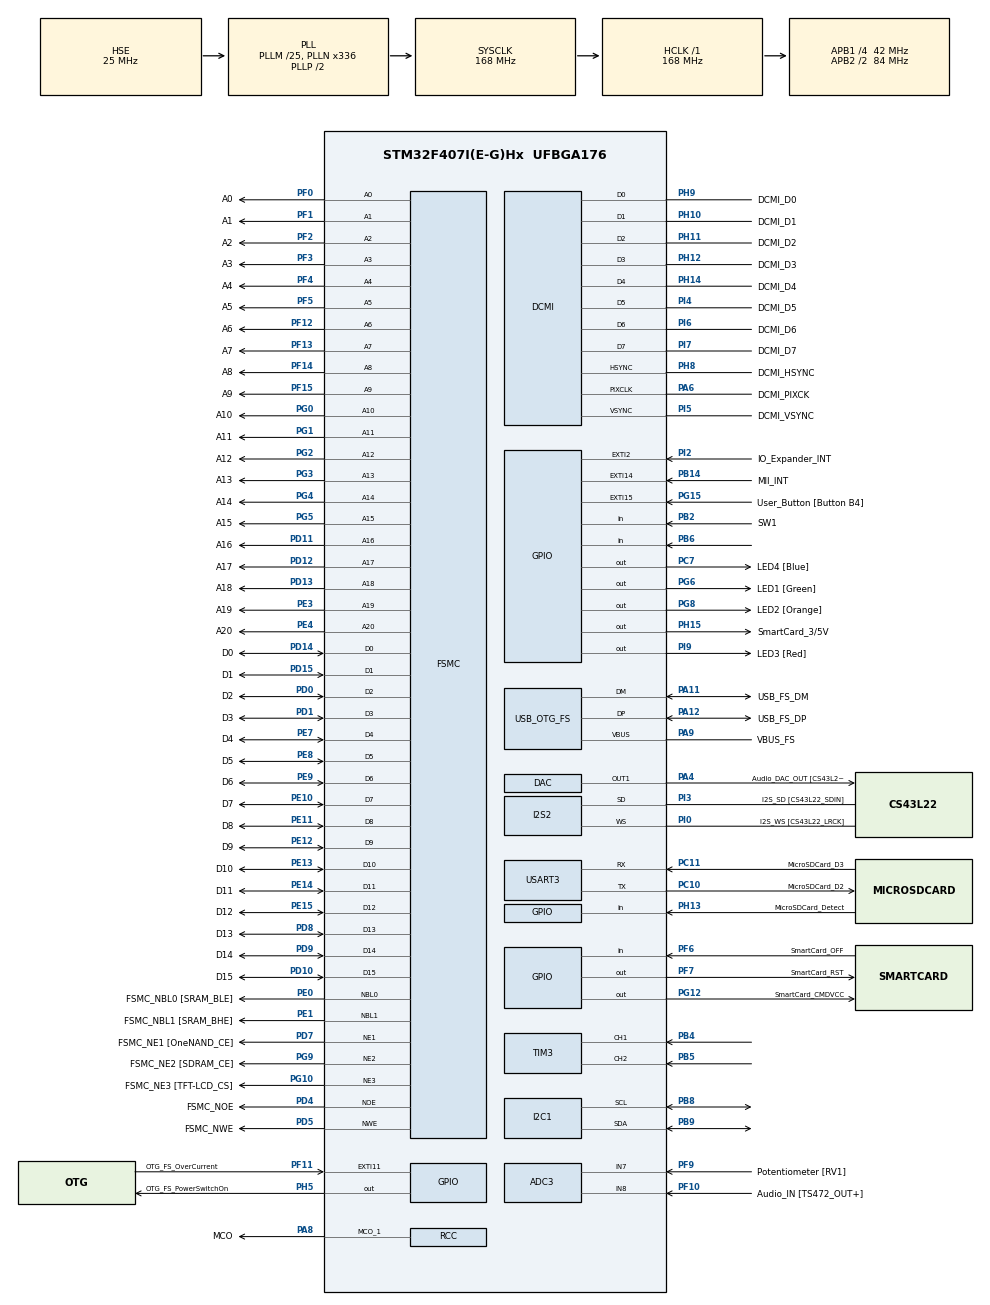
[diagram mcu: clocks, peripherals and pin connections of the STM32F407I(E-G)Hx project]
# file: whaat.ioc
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ADC3.Channel=ADC_CHANNEL_7
ADC3.Channel-0\#ChannelRegularConversion=ADC_CHANNEL_7
ADC3.NbrOfConversionFlag=1
ADC3.Rank-0\#ChannelRegularConversion=1
ADC3.SamplingTime-0\#ChannelRegularConversion=ADC_SAMPLETIME_3CYCLES
Mcu.Family=STM32F4
Mcu.Name=STM32F407I(E-G)Hx
Mcu.Package=UFBGA176
NVIC.OTG_FS_IRQn=true\:0\:0\:false\:false\:true\:true\:true\:true
NVIC.PriorityGroup=NVIC_PRIORITYGROUP_0
PA0-WKUP.GPIO_Label=WAKEUP [Button B2]
PA0-WKUP.Signal=SYS_WKUP
PA1.GPIO_Label=MII_RX_CLK/RMII_REF_CLK
PA1.GPIO_Mode=GPIO_MODE_AF_PP
PA1.GPIO_PuPd=GPIO_NOPULL
PA1.GPIO_Speed=GPIO_SPEED_FREQ_LOW
PA1.Signal=ETH_RX_CLK
PA10.GPIO_Label=USB_FS_ID
PA10.GPIO_Mode=GPIO_MODE_AF_PP
PA10.GPIO_PuPd=GPIO_NOPULL
PA10.GPIO_Speed=GPIO_SPEED_FREQ_LOW
PA10.Signal=USB_OTG_FS_ID
PA11.GPIO_Label=USB_FS_DM
PA11.GPIO_Mode=GPIO_MODE_AF_PP
PA11.GPIO_PuPd=GPIO_NOPULL
PA11.GPIO_Speed=GPIO_SPEED_FREQ_LOW
PA11.Mode=Device_Only
PA11.Signal=USB_OTG_FS_DM
PA12.GPIO_Label=USB_FS_DP
PA12.GPIO_Mode=GPIO_MODE_AF_PP
PA12.GPIO_PuPd=GPIO_NOPULL
PA12.GPIO_Speed=GPIO_SPEED_FREQ_LOW
PA12.Mode=Device_Only
PA12.Signal=USB_OTG_FS_DP
PA13.GPIO_Label=TMS/SWDIO
PA13.Mode=Serial_Wire
PA13.Signal=SYS_JTMS-SWDIO
PA14.GPIO_Label=TCK/SWCLK
PA14.Mode=Serial_Wire
PA14.Signal=SYS_JTCK-SWCLK
PA15.GPIO_Label=TDI
PA15.Signal=SYS_JTDI
PA2.GPIO_Label=MII_MDIO
PA2.GPIO_Mode=GPIO_MODE_AF_PP
PA2.GPIO_PuPd=GPIO_NOPULL
PA2.GPIO_Speed=GPIO_SPEED_FREQ_LOW
PA2.Signal=ETH_MDIO
PA3.GPIO_Label=ULPI_D0
PA3.GPIO_Mode=GPIO_MODE_AF_PP
PA3.GPIO_PuPd=GPIO_NOPULL
PA3.GPIO_Speed=GPIO_SPEED_FREQ_VERY_HIGH
PA3.Signal=USB_OTG_HS_ULPI_D0
PA4.GPIO_Label=Audio_DAC_OUT [CS43L22_AIN1]
PA4.GPIO_Mode=GPIO_MODE_ANALOG
PA4.GPIO_PuPd=GPIO_NOPULL
PA4.Signal=COMP_DAC1_group
PA5.GPIO_Label=ULPI_CLK
PA5.GPIO_Mode=GPIO_MODE_AF_PP
PA5.GPIO_PuPd=GPIO_NOPULL
PA5.GPIO_Speed=GPIO_SPEED_FREQ_VERY_HIGH
PA5.Signal=USB_OTG_HS_ULPI_CK
PA6.GPIO_Label=DCMI_PIXCK
PA6.GPIO_Mode=GPIO_MODE_AF_PP
PA6.GPIO_PuPd=GPIO_NOPULL
PA6.GPIO_Speed=GPIO_SPEED_FREQ_LOW
PA6.Mode=Slave_8_bits_External_Synchro
PA6.Signal=DCMI_PIXCLK
PA7.GPIO_Label=MII_RX_DV/RMII_CRSDV
PA7.GPIO_Mode=GPIO_MODE_AF_PP
PA7.GPIO_PuPd=GPIO_NOPULL
PA7.GPIO_Speed=GPIO_SPEED_FREQ_LOW
PA7.Signal=ETH_RX_DV
PA8.GPIO_Label=MCO
PA8.GPIO_Mode=GPIO_MODE_AF_PP
PA8.GPIO_PuPd=GPIO_NOPULL
PA8.GPIO_Speed=GPIO_SPEED_FREQ_LOW
PA8.Mode=Clock-out-1
PA8.Signal=RCC_MCO_1
PA9.GPIO_Label=VBUS_FS
PA9.GPIO_Mode=GPIO_MODE_INPUT
PA9.GPIO_PuPd=GPIO_NOPULL
PA9.Mode=Activate_VBUS
PA9.Signal=USB_OTG_FS_VBUS
PB0.GPIO_Label=ULPI_D1
PB0.GPIO_Mode=GPIO_MODE_AF_PP
PB0.GPIO_PuPd=GPIO_NOPULL
PB0.GPIO_Speed=GPIO_SPEED_FREQ_VERY_HIGH
PB0.Signal=USB_OTG_HS_ULPI_D1
PB1.GPIO_Label=ULPI_D2
PB1.GPIO_Mode=GPIO_MODE_AF_PP
PB1.GPIO_PuPd=GPIO_NOPULL
PB1.GPIO_Speed=GPIO_SPEED_FREQ_VERY_HIGH
PB1.Signal=USB_OTG_HS_ULPI_D2
PB10.GPIO_Label=ULPI_D3
PB10.GPIO_Mode=GPIO_MODE_AF_PP
PB10.GPIO_PuPd=GPIO_NOPULL
PB10.GPIO_Speed=GPIO_SPEED_FREQ_VERY_HIGH
PB10.Signal=USB_OTG_HS_ULPI_D3
PB11.GPIO_Label=ULPI_D4
PB11.GPIO_Mode=GPIO_MODE_AF_PP
PB11.GPIO_PuPd=GPIO_NOPULL
PB11.GPIO_Speed=GPIO_SPEED_FREQ_VERY_HIGH
PB11.Signal=USB_OTG_HS_ULPI_D4
PB12.GPIO_Label=ULPI_D5
PB12.GPIO_Mode=GPIO_MODE_AF_PP
PB12.GPIO_PuPd=GPIO_NOPULL
PB12.GPIO_Speed=GPIO_SPEED_FREQ_VERY_HIGH
PB12.Signal=USB_OTG_HS_ULPI_D5
PB13.GPIO_Label=ULPI_D6
PB13.GPIO_Mode=GPIO_MODE_AF_PP
PB13.GPIO_PuPd=GPIO_NOPULL
PB13.GPIO_Speed=GPIO_SPEED_FREQ_VERY_HIGH
PB13.Signal=USB_OTG_HS_ULPI_D6
PB14.GPIO_Label=MII_INT
PB14.GPIO_ModeDefaultEXTI=GPIO_MODE_EVT_RISING
PB14.GPIO_PuPd=GPIO_NOPULL
PB14.Signal=GPXTI14
PB2.GPIO_Label=SW1
PB2.GPIO_Mode=GPIO_MODE_INPUT
PB2.GPIO_PuPd=GPIO_NOPULL
PB2.Signal=GPIO_Input
PB3.GPIO_Label=TDO/SWO
PB3.Signal=SYS_JTDO-SWO
PB4.Signal=S_TIM3_CH1
PB5.Signal=S_TIM3_CH2
PB6.GPIO_PuPd=GPIO_PULLDOWN
PB6.Signal=GPIO_Input
PB7.GPIO_Label=FSMC_NL [OneNAND_AVD]
PB7.GPIO_Mode=GPIO_MODE_AF_PP
PB7.GPIO_PuPd=GPIO_NOPULL
PB7.GPIO_Speed=GPIO_SPEED_FREQ_LOW
PB7.Signal=FSMC_NL
PB8.Mode=I2C
PB8.Signal=I2C1_SCL
PB9.Mode=I2C
PB9.Signal=I2C1_SDA
PC0.GPIO_Label=ULPI_STP
PC0.GPIO_Mode=GPIO_MODE_AF_PP
PC0.GPIO_PuPd=GPIO_NOPULL
PC0.GPIO_Speed=GPIO_SPEED_FREQ_VERY_HIGH
PC0.Signal=USB_OTG_HS_ULPI_STP
PC1.GPIO_Label=MII_MDC
PC1.GPIO_Mode=GPIO_MODE_AF_PP
PC1.GPIO_PuPd=GPIO_NOPULL
PC1.GPIO_Speed=GPIO_SPEED_FREQ_LOW
PC1.Signal=ETH_MDC
PC10.GPIO_Label=MicroSDCard_D2
PC10.GPIO_Mode=GPIO_MODE_AF_PP
PC10.GPIO_PuPd=GPIO_NOPULL
PC10.GPIO_Speed=GPIO_SPEED_FREQ_LOW
PC10.Mode=Asynchronous
PC10.Signal=USART3_TX
PC11.GPIO_Label=MicroSDCard_D3
PC11.GPIO_Mode=GPIO_MODE_AF_PP
PC11.GPIO_PuPd=GPIO_NOPULL
PC11.GPIO_Speed=GPIO_SPEED_FREQ_LOW
PC11.Mode=Asynchronous
PC11.Signal=USART3_RX
PC12.GPIO_Label=MicroSDCard_CLK
PC12.GPIO_Mode=GPIO_MODE_AF_PP
PC12.GPIO_PuPd=GPIO_NOPULL
PC12.GPIO_Speed=GPIO_SPEED_FREQ_LOW
PC12.Signal=SDIO_CK
PC13-ANTI_TAMP.GPIO_Label=Anti_Tamper [Button B3]
PC13-ANTI_TAMP.Signal=RTC_AF1
PC14-OSC32_IN.GPIO_Label=PC14-OSC32_IN
PC14-OSC32_IN.Mode=LSE-External-Oscillator
PC14-OSC32_IN.Signal=RCC_OSC32_IN
PC15-OSC32_OUT.GPIO_Label=PC15-OSC32_OUT
PC15-OSC32_OUT.Mode=LSE-External-Oscillator
PC15-OSC32_OUT.Signal=RCC_OSC32_OUT
PC2.GPIO_Label=MII_TXD2
PC2.GPIO_Mode=GPIO_MODE_AF_PP
PC2.GPIO_PuPd=GPIO_NOPULL
PC2.GPIO_Speed=GPIO_SPEED_FREQ_LOW
PC2.Signal=ETH_TXD2
PC3.GPIO_Label=MII_TX_CLK
PC3.GPIO_Mode=GPIO_MODE_AF_PP
PC3.GPIO_PuPd=GPIO_NOPULL
PC3.GPIO_Speed=GPIO_SPEED_FREQ_LOW
PC3.Signal=ETH_TX_CLK
PC4.GPIO_Label=MII_RXD0
PC4.GPIO_Mode=GPIO_MODE_AF_PP
PC4.GPIO_PuPd=GPIO_NOPULL
PC4.GPIO_Speed=GPIO_SPEED_FREQ_LOW
PC4.Signal=ETH_RXD0
PC5.GPIO_Label=MII_RXD1
PC5.GPIO_Mode=GPIO_MODE_AF_PP
PC5.GPIO_PuPd=GPIO_NOPULL
PC5.GPIO_Speed=GPIO_SPEED_FREQ_LOW
PC5.Signal=ETH_RXD1
PC7.GPIO_Label=LED4 [Blue]
PC7.GPIO_Mode=GPIO_MODE_OUTPUT_PP
PC7.GPIO_ModeDefaultOutputPP=GPIO_MODE_OUTPUT_PP
PC7.GPIO_PuPd=GPIO_NOPULL
PC7.GPIO_Speed=GPIO_SPEED_FREQ_LOW
PC7.Signal=GPIO_Output
PC8.GPIO_Label=MicroSDCard_D0
PC8.GPIO_Mode=GPIO_MODE_AF_PP
PC8.GPIO_PuPd=GPIO_NOPULL
PC8.GPIO_Speed=GPIO_SPEED_FREQ_LOW
PC8.Signal=SDIO_D0
PC9.GPIO_Label=MicroSDCard_D1
PC9.GPIO_Mode=GPIO_MODE_AF_PP
PC9.GPIO_PuPd=GPIO_NOPULL
PC9.GPIO_Speed=GPIO_SPEED_FREQ_LOW
PC9.Signal=SDIO_D1
PD0.GPIO_Label=D2
PD0.GPIO_Mode=GPIO_MODE_AF_PP
PD0.GPIO_PuPd=GPIO_NOPULL
PD0.GPIO_Speed=GPIO_SPEED_FREQ_LOW
PD0.Signal=FSMC_D2_DA2
PD1.GPIO_Label=D3
PD1.GPIO_Mode=GPIO_MODE_AF_PP
PD1.GPIO_PuPd=GPIO_NOPULL
PD1.GPIO_Speed=GPIO_SPEED_FREQ_LOW
PD1.Signal=FSMC_D3_DA3
PD10.GPIO_Label=D15
PD10.GPIO_Mode=GPIO_MODE_AF_PP
PD10.GPIO_PuPd=GPIO_NOPULL
PD10.GPIO_Speed=GPIO_SPEED_FREQ_LOW
PD10.Signal=FSMC_D15_DA15
PD11.GPIO_Label=A16
PD11.GPIO_Mode=GPIO_MODE_AF_PP
PD11.GPIO_PuPd=GPIO_NOPULL
PD11.GPIO_Speed=GPIO_SPEED_FREQ_LOW
PD11.Signal=FSMC_A16_CLE
PD12.GPIO_Label=A17
PD12.GPIO_Mode=GPIO_MODE_AF_PP
PD12.GPIO_PuPd=GPIO_NOPULL
PD12.GPIO_Speed=GPIO_SPEED_FREQ_LOW
PD12.Signal=FSMC_A17_ALE
PD13.GPIO_Label=A18
PD13.GPIO_Mode=GPIO_MODE_AF_PP
PD13.GPIO_PuPd=GPIO_NOPULL
PD13.GPIO_Speed=GPIO_SPEED_FREQ_LOW
PD13.Signal=FSMC_A18
PD14.GPIO_Label=D0
PD14.GPIO_Mode=GPIO_MODE_AF_PP
PD14.GPIO_PuPd=GPIO_NOPULL
PD14.GPIO_Speed=GPIO_SPEED_FREQ_LOW
PD14.Signal=FSMC_D0_DA0
PD15.GPIO_Label=D1
PD15.GPIO_Mode=GPIO_MODE_AF_PP
PD15.GPIO_PuPd=GPIO_NOPULL
PD15.GPIO_Speed=GPIO_SPEED_FREQ_LOW
PD15.Signal=FSMC_D1_DA1
PD2.GPIO_Label=MicroSDCard_CMD
PD2.GPIO_Mode=GPIO_MODE_AF_PP
PD2.GPIO_PuPd=GPIO_NOPULL
PD2.GPIO_Speed=GPIO_SPEED_FREQ_LOW
PD2.Signal=SDIO_CMD
PD3.GPIO_Label=FSMC_CLK [OneNAND_CLK]
PD3.GPIO_Mode=GPIO_MODE_AF_PP
PD3.GPIO_PuPd=GPIO_NOPULL
PD3.GPIO_Speed=GPIO_SPEED_FREQ_LOW
PD3.Signal=FSMC_CLK
PD4.GPIO_Label=FSMC_NOE
PD4.GPIO_Mode=GPIO_MODE_AF_PP
PD4.GPIO_PuPd=GPIO_NOPULL
PD4.GPIO_Speed=GPIO_SPEED_FREQ_LOW
PD4.Signal=FSMC_NOE
PD5.GPIO_Label=FSMC_NWE
PD5.GPIO_Mode=GPIO_MODE_AF_PP
PD5.GPIO_PuPd=GPIO_NOPULL
PD5.GPIO_Speed=GPIO_SPEED_FREQ_LOW
PD5.Signal=FSMC_NWE
PD6.GPIO_Label=FSMC_NWAIT [OneNAND_RDY]
PD6.GPIO_Mode=GPIO_MODE_AF_PP
PD6.GPIO_PuPd=GPIO_NOPULL
PD6.GPIO_Speed=GPIO_SPEED_FREQ_LOW
PD6.Signal=FSMC_NWAIT
PD7.GPIO_Label=FSMC_NE1 [OneNAND_CE]
PD7.GPIO_Mode=GPIO_MODE_AF_PP
PD7.GPIO_PuPd=GPIO_NOPULL
PD7.GPIO_Speed=GPIO_SPEED_FREQ_LOW
PD7.Mode=NorPsramChipSelect1_1
PD7.Signal=FSMC_NE1
PD8.GPIO_Label=D13
PD8.GPIO_Mode=GPIO_MODE_AF_PP
PD8.GPIO_PuPd=GPIO_NOPULL
PD8.GPIO_Speed=GPIO_SPEED_FREQ_LOW
PD8.Signal=FSMC_D13_DA13
PD9.GPIO_Label=D14
PD9.GPIO_Mode=GPIO_MODE_AF_PP
PD9.GPIO_PuPd=GPIO_NOPULL
PD9.GPIO_Speed=GPIO_SPEED_FREQ_LOW
PD9.Signal=FSMC_D14_DA14
PE0.GPIO_Label=FSMC_NBL0 [SRAM_BLE]
PE0.GPIO_Mode=GPIO_MODE_AF_PP
PE0.GPIO_PuPd=GPIO_NOPULL
PE0.GPIO_Speed=GPIO_SPEED_FREQ_LOW
PE0.Signal=FSMC_NBL0
PE1.GPIO_Label=FSMC_NBL1 [SRAM_BHE]
PE1.GPIO_Mode=GPIO_MODE_AF_PP
PE1.GPIO_PuPd=GPIO_NOPULL
PE1.GPIO_Speed=GPIO_SPEED_FREQ_LOW
PE1.Signal=FSMC_NBL1
PE10.GPIO_Label=D7
PE10.GPIO_Mode=GPIO_MODE_AF_PP
PE10.GPIO_PuPd=GPIO_NOPULL
PE10.GPIO_Speed=GPIO_SPEED_FREQ_LOW
PE10.Signal=FSMC_D7_DA7
PE11.GPIO_Label=D8
PE11.GPIO_Mode=GPIO_MODE_AF_PP
PE11.GPIO_PuPd=GPIO_NOPULL
PE11.GPIO_Speed=GPIO_SPEED_FREQ_LOW
PE11.Signal=FSMC_D8_DA8
PE12.GPIO_Label=D9
PE12.GPIO_Mode=GPIO_MODE_AF_PP
PE12.GPIO_PuPd=GPIO_NOPULL
PE12.GPIO_Speed=GPIO_SPEED_FREQ_LOW
PE12.Signal=FSMC_D9_DA9
PE13.GPIO_Label=D10
PE13.GPIO_Mode=GPIO_MODE_AF_PP
PE13.GPIO_PuPd=GPIO_NOPULL
PE13.GPIO_Speed=GPIO_SPEED_FREQ_LOW
PE13.Signal=FSMC_D10_DA10
PE14.GPIO_Label=D11
PE14.GPIO_Mode=GPIO_MODE_AF_PP
PE14.GPIO_PuPd=GPIO_NOPULL
PE14.GPIO_Speed=GPIO_SPEED_FREQ_LOW
PE14.Signal=FSMC_D11_DA11
PE15.GPIO_Label=D12
PE15.GPIO_Mode=GPIO_MODE_AF_PP
PE15.GPIO_PuPd=GPIO_NOPULL
PE15.GPIO_Speed=GPIO_SPEED_FREQ_LOW
PE15.Signal=FSMC_D12_DA12
PE2.GPIO_Label=TRACE_CLK
PE2.Signal=SYS_TRACECLK
PE3.GPIO_Label=A19
PE3.GPIO_Mode=GPIO_MODE_AF_PP
PE3.GPIO_PuPd=GPIO_NOPULL
PE3.GPIO_Speed=GPIO_SPEED_FREQ_LOW
PE3.Signal=FSMC_A19
PE4.GPIO_Label=A20
PE4.GPIO_Mode=GPIO_MODE_AF_PP
PE4.GPIO_PuPd=GPIO_NOPULL
PE4.GPIO_Speed=GPIO_SPEED_FREQ_LOW
PE4.Signal=FSMC_A20
PE5.GPIO_Label=TRACE_D2
PE5.Signal=SYS_TRACED2
PE6.GPIO_Label=TRACE_D3
PE6.Signal=SYS_TRACED3
PE7.GPIO_Label=D4
PE7.GPIO_Mode=GPIO_MODE_AF_PP
PE7.GPIO_PuPd=GPIO_NOPULL
PE7.GPIO_Speed=GPIO_SPEED_FREQ_LOW
PE7.Signal=FSMC_D4_DA4
PE8.GPIO_Label=D5
PE8.GPIO_Mode=GPIO_MODE_AF_PP
PE8.GPIO_PuPd=GPIO_NOPULL
PE8.GPIO_Speed=GPIO_SPEED_FREQ_LOW
PE8.Signal=FSMC_D5_DA5
PE9.GPIO_Label=D6
PE9.GPIO_Mode=GPIO_MODE_AF_PP
PE9.GPIO_PuPd=GPIO_NOPULL
PE9.GPIO_Speed=GPIO_SPEED_FREQ_LOW
PE9.Signal=FSMC_D6_DA6
PF0.GPIO_Label=A0
PF0.GPIO_Mode=GPIO_MODE_AF_PP
PF0.GPIO_PuPd=GPIO_NOPULL
PF0.GPIO_Speed=GPIO_SPEED_FREQ_LOW
PF0.Signal=FSMC_A0
PF1.GPIO_Label=A1
PF1.GPIO_Mode=GPIO_MODE_AF_PP
PF1.GPIO_PuPd=GPIO_NOPULL
PF1.GPIO_Speed=GPIO_SPEED_FREQ_LOW
PF1.Signal=FSMC_A1
PF10.GPIO_Label=Audio_IN [TS472_OUT+]
PF10.GPIO_Mode=GPIO_MODE_ANALOG
PF10.GPIO_PuPd=GPIO_NOPULL
PF10.Mode=IN8
PF10.Signal=ADC3_IN8
PF11.GPIO_Label=OTG_FS_OverCurrent
PF11.GPIO_ModeDefaultEXTI=GPIO_MODE_EVT_RISING
PF11.GPIO_PuPd=GPIO_NOPULL
PF11.Signal=GPXTI11
PF12.GPIO_Label=A6
PF12.GPIO_Mode=GPIO_MODE_AF_PP
PF12.GPIO_PuPd=GPIO_NOPULL
PF12.GPIO_Speed=GPIO_SPEED_FREQ_LOW
PF12.Signal=FSMC_A6
PF13.GPIO_Label=A7
PF13.GPIO_Mode=GPIO_MODE_AF_PP
PF13.GPIO_PuPd=GPIO_NOPULL
PF13.GPIO_Speed=GPIO_SPEED_FREQ_LOW
PF13.Signal=FSMC_A7
PF14.GPIO_Label=A8
PF14.GPIO_Mode=GPIO_MODE_AF_PP
PF14.GPIO_PuPd=GPIO_NOPULL
PF14.GPIO_Speed=GPIO_SPEED_FREQ_LOW
PF14.Signal=FSMC_A8
PF15.GPIO_Label=A9
PF15.GPIO_Mode=GPIO_MODE_AF_PP
PF15.GPIO_PuPd=GPIO_NOPULL
PF15.GPIO_Speed=GPIO_SPEED_FREQ_LOW
PF15.Signal=FSMC_A9
PF2.GPIO_Label=A2
PF2.GPIO_Mode=GPIO_MODE_AF_PP
PF2.GPIO_PuPd=GPIO_NOPULL
PF2.GPIO_Speed=GPIO_SPEED_FREQ_LOW
PF2.Signal=FSMC_A2
PF3.GPIO_Label=A3
PF3.GPIO_Mode=GPIO_MODE_AF_PP
PF3.GPIO_PuPd=GPIO_NOPULL
PF3.GPIO_Speed=GPIO_SPEED_FREQ_LOW
PF3.Signal=FSMC_A3
PF4.GPIO_Label=A4
PF4.GPIO_Mode=GPIO_MODE_AF_PP
PF4.GPIO_PuPd=GPIO_NOPULL
PF4.GPIO_Speed=GPIO_SPEED_FREQ_LOW
PF4.Signal=FSMC_A4
PF5.GPIO_Label=A5
PF5.GPIO_Mode=GPIO_MODE_AF_PP
PF5.GPIO_PuPd=GPIO_NOPULL
PF5.GPIO_Speed=GPIO_SPEED_FREQ_LOW
PF5.Signal=FSMC_A5
PF6.GPIO_Label=SmartCard_OFF
PF6.GPIO_Mode=GPIO_MODE_INPUT
PF6.GPIO_PuPd=GPIO_NOPULL
PF6.Signal=GPIO_Input
PF7.GPIO_Label=SmartCard_RST
PF7.GPIO_Mode=GPIO_MODE_OUTPUT_PP
PF7.GPIO_ModeDefaultOutputPP=GPIO_MODE_OUTPUT_PP
PF7.GPIO_PuPd=GPIO_NOPULL
PF7.GPIO_Speed=GPIO_SPEED_FREQ_LOW
PF7.Signal=GPIO_Output
PF9.GPIO_Label=Potentiometer [RV1]
PF9.GPIO_Mode=GPIO_MODE_ANALOG
PF9.GPIO_PuPd=GPIO_NOPULL
PF9.Mode=IN7
PF9.Signal=ADC3_IN7
PG0.GPIO_Label=A10
PG0.GPIO_Mode=GPIO_MODE_AF_PP
PG0.GPIO_PuPd=GPIO_NOPULL
PG0.GPIO_Speed=GPIO_SPEED_FREQ_LOW
PG0.Signal=FSMC_A10
PG1.GPIO_Label=A11
PG1.GPIO_Mode=GPIO_MODE_AF_PP
PG1.GPIO_PuPd=GPIO_NOPULL
PG1.GPIO_Speed=GPIO_SPEED_FREQ_LOW
PG1.Signal=FSMC_A11
PG10.GPIO_Label=FSMC_NE3 [TFT-LCD_CS]
PG10.GPIO_Mode=GPIO_MODE_AF_PP
PG10.GPIO_PuPd=GPIO_NOPULL
PG10.GPIO_Speed=GPIO_SPEED_FREQ_LOW
PG10.Mode=NorPsramChipSelect3_3
PG10.Signal=FSMC_NE3
PG11.GPIO_Label=MII_TX_EN
PG11.GPIO_Mode=GPIO_MODE_AF_PP
PG11.GPIO_PuPd=GPIO_NOPULL
PG11.GPIO_Speed=GPIO_SPEED_FREQ_LOW
PG11.Signal=ETH_TX_EN
PG12.GPIO_Label=SmartCard_CMDVCC
PG12.GPIO_Mode=GPIO_MODE_OUTPUT_PP
PG12.GPIO_ModeDefaultOutputPP=GPIO_MODE_OUTPUT_PP
PG12.GPIO_PuPd=GPIO_NOPULL
PG12.GPIO_Speed=GPIO_SPEED_FREQ_LOW
PG12.Signal=GPIO_Output
PG13.GPIO_Label=MII_TXD0
PG13.GPIO_Mode=GPIO_MODE_AF_PP
PG13.GPIO_PuPd=GPIO_NOPULL
PG13.GPIO_Speed=GPIO_SPEED_FREQ_LOW
PG13.Signal=ETH_TXD0
PG14.GPIO_Label=MII_TXD1
PG14.GPIO_Mode=GPIO_MODE_AF_PP
PG14.GPIO_PuPd=GPIO_NOPULL
PG14.GPIO_Speed=GPIO_SPEED_FREQ_LOW
PG14.Signal=ETH_TXD1
PG15.GPIO_Label=User_Button [Button B4]
PG15.GPIO_ModeDefaultEXTI=GPIO_MODE_EVT_RISING
PG15.GPIO_PuPd=GPIO_NOPULL
PG15.Signal=GPXTI15
PG2.GPIO_Label=A12
PG2.GPIO_Mode=GPIO_MODE_AF_PP
PG2.GPIO_PuPd=GPIO_NOPULL
PG2.GPIO_Speed=GPIO_SPEED_FREQ_LOW
PG2.Signal=FSMC_A12
PG3.GPIO_Label=A13
PG3.GPIO_Mode=GPIO_MODE_AF_PP
PG3.GPIO_PuPd=GPIO_NOPULL
PG3.GPIO_Speed=GPIO_SPEED_FREQ_LOW
PG3.Signal=FSMC_A13
PG4.GPIO_Label=A14
PG4.GPIO_Mode=GPIO_MODE_AF_PP
PG4.GPIO_PuPd=GPIO_NOPULL
PG4.GPIO_Speed=GPIO_SPEED_FREQ_LOW
PG4.Signal=FSMC_A14
PG5.GPIO_Label=A15
PG5.GPIO_Mode=GPIO_MODE_AF_PP
PG5.GPIO_PuPd=GPIO_NOPULL
PG5.GPIO_Speed=GPIO_SPEED_FREQ_LOW
PG5.Signal=FSMC_A15
PG6.GPIO_Label=LED1 [Green]
PG6.GPIO_Mode=GPIO_MODE_OUTPUT_PP
PG6.GPIO_ModeDefaultOutputPP=GPIO_MODE_OUTPUT_PP
PG6.GPIO_PuPd=GPIO_NOPULL
PG6.GPIO_Speed=GPIO_SPEED_FREQ_LOW
PG6.Signal=GPIO_Output
PG7.GPIO_Label=SmartCard_CLK
PG7.GPIO_Mode=GPIO_MODE_AF_PP
PG7.GPIO_PuPd=GPIO_NOPULL
PG7.GPIO_Speed=GPIO_SPEED_FREQ_LOW
PG7.Signal=USART6_CK
PG8.GPIO_Label=LED2 [Orange]
PG8.GPIO_Mode=GPIO_MODE_OUTPUT_PP
PG8.GPIO_ModeDefaultOutputPP=GPIO_MODE_OUTPUT_PP
PG8.GPIO_PuPd=GPIO_NOPULL
PG8.GPIO_Speed=GPIO_SPEED_FREQ_LOW
PG8.Signal=GPIO_Output
PG9.GPIO_Label=FSMC_NE2 [SDRAM_CE]
PG9.GPIO_Mode=GPIO_MODE_AF_PP
PG9.GPIO_PuPd=GPIO_NOPULL
PG9.GPIO_Speed=GPIO_SPEED_FREQ_LOW
PG9.Mode=NorPsramChipSelect2_2
PG9.Signal=FSMC_NE2
PH0-OSC_IN.GPIO_Label=PH0-OSC_IN
PH0-OSC_IN.Mode=HSE-External-Oscillator
PH0-OSC_IN.Signal=RCC_OSC_IN
PH1-OSC_OUT.GPIO_Label=PH1-OSC_OUT
PH1-OSC_OUT.Mode=HSE-External-Oscillator
PH1-OSC_OUT.Signal=RCC_OSC_OUT
PH10.GPIO_Label=DCMI_D1
PH10.GPIO_Mode=GPIO_MODE_AF_PP
PH10.GPIO_PuPd=GPIO_NOPULL
PH10.GPIO_Speed=GPIO_SPEED_FREQ_LOW
PH10.Mode=Slave_8_bits_External_Synchro
PH10.Signal=DCMI_D1
PH11.GPIO_Label=DCMI_D2
PH11.GPIO_Mode=GPIO_MODE_AF_PP
PH11.GPIO_PuPd=GPIO_NOPULL
PH11.GPIO_Speed=GPIO_SPEED_FREQ_LOW
PH11.Mode=Slave_8_bits_External_Synchro
PH11.Signal=DCMI_D2
PH12.GPIO_Label=DCMI_D3
PH12.GPIO_Mode=GPIO_MODE_AF_PP
PH12.GPIO_PuPd=GPIO_NOPULL
PH12.GPIO_Speed=GPIO_SPEED_FREQ_LOW
PH12.Mode=Slave_8_bits_External_Synchro
PH12.Signal=DCMI_D3
PH13.GPIO_Label=MicroSDCard_Detect
PH13.GPIO_Mode=GPIO_MODE_INPUT
PH13.GPIO_PuPd=GPIO_PULLUP
PH13.Signal=GPIO_Input
PH14.GPIO_Label=DCMI_D4
PH14.GPIO_Mode=GPIO_MODE_AF_PP
PH14.GPIO_PuPd=GPIO_NOPULL
PH14.GPIO_Speed=GPIO_SPEED_FREQ_LOW
PH14.Mode=Slave_8_bits_External_Synchro
PH14.Signal=DCMI_D4
PH15.GPIO_Label=SmartCard_3/5V
PH15.GPIO_Mode=GPIO_MODE_OUTPUT_PP
PH15.GPIO_ModeDefaultOutputPP=GPIO_MODE_OUTPUT_PP
PH15.GPIO_PuPd=GPIO_NOPULL
PH15.GPIO_Speed=GPIO_SPEED_FREQ_LOW
PH15.Signal=GPIO_Output
PH2.GPIO_Label=MII_CRS
PH2.GPIO_Mode=GPIO_MODE_AF_PP
PH2.GPIO_PuPd=GPIO_NOPULL
PH2.GPIO_Speed=GPIO_SPEED_FREQ_LOW
PH2.Signal=ETH_CRS
PH3.GPIO_Label=MII_COL
PH3.GPIO_Mode=GPIO_MODE_AF_PP
PH3.GPIO_PuPd=GPIO_NOPULL
PH3.GPIO_Speed=GPIO_SPEED_FREQ_LOW
PH3.Signal=ETH_COL
PH4.GPIO_Label=ULPI_NXT
PH4.GPIO_Mode=GPIO_MODE_AF_PP
PH4.GPIO_PuPd=GPIO_NOPULL
PH4.GPIO_Speed=GPIO_SPEED_FREQ_VERY_HIGH
PH4.Signal=USB_OTG_HS_ULPI_NXT
PH5.GPIO_Label=OTG_FS_PowerSwitchOn
PH5.GPIO_Mode=GPIO_MODE_OUTPUT_PP
PH5.GPIO_ModeDefaultOutputPP=GPIO_MODE_OUTPUT_PP
PH5.GPIO_PuPd=GPIO_NOPULL
PH5.GPIO_Speed=GPIO_SPEED_FREQ_LOW
PH5.Signal=GPIO_Output
PH6.GPIO_Label=MII_RXD2
PH6.GPIO_Mode=GPIO_MODE_AF_PP
PH6.GPIO_PuPd=GPIO_NOPULL
PH6.GPIO_Speed=GPIO_SPEED_FREQ_LOW
PH6.Signal=ETH_RXD2
PH7.GPIO_Label=MII_RXD3
PH7.GPIO_Mode=GPIO_MODE_AF_PP
PH7.GPIO_PuPd=GPIO_NOPULL
PH7.GPIO_Speed=GPIO_SPEED_FREQ_LOW
PH7.Signal=ETH_RXD3
PH8.GPIO_Label=DCMI_HSYNC
PH8.GPIO_Mode=GPIO_MODE_AF_PP
PH8.GPIO_PuPd=GPIO_NOPULL
PH8.GPIO_Speed=GPIO_SPEED_FREQ_LOW
PH8.Mode=Slave_8_bits_External_Synchro
PH8.Signal=DCMI_HSYNC
PH9.GPIO_Label=DCMI_D0
PH9.GPIO_Mode=GPIO_MODE_AF_PP
PH9.GPIO_PuPd=GPIO_NOPULL
PH9.GPIO_Speed=GPIO_SPEED_FREQ_LOW
PH9.Mode=Slave_8_bits_External_Synchro
PH9.Signal=DCMI_D0
PI0.GPIO_Label=I2S_WS [CS43L22_LRCK]
PI0.GPIO_Mode=GPIO_MODE_AF_PP
PI0.GPIO_PuPd=GPIO_NOPULL
PI0.GPIO_Speed=GPIO_SPEED_FREQ_LOW
PI0.Mode=Half_Duplex_Master
PI0.Signal=I2S2_WS
PI10.GPIO_Label=MII_RX_ER
PI10.GPIO_Mode=GPIO_MODE_AF_PP
PI10.GPIO_PuPd=GPIO_NOPULL
PI10.GPIO_Speed=GPIO_SPEED_FREQ_LOW
PI10.Signal=ETH_RX_ER
PI11.GPIO_Label=ULPI_DIR
PI11.GPIO_Mode=GPIO_MODE_AF_PP
PI11.GPIO_PuPd=GPIO_NOPULL
PI11.GPIO_Speed=GPIO_SPEED_FREQ_VERY_HIGH
PI11.Signal=USB_OTG_HS_ULPI_DIR
PI2.GPIO_Label=IO_Expander_INT
PI2.GPIO_ModeDefaultEXTI=GPIO_MODE_EVT_RISING
PI2.GPIO_PuPd=GPIO_NOPULL
PI2.Signal=GPXTI2
PI3.GPIO_Label=I2S_SD [CS43L22_SDIN]
PI3.GPIO_Mode=GPIO_MODE_AF_PP
PI3.GPIO_PuPd=GPIO_NOPULL
PI3.GPIO_Speed=GPIO_SPEED_FREQ_LOW
PI3.Mode=Half_Duplex_Master
PI3.Signal=I2S2_SD
PI4.GPIO_Label=DCMI_D5
PI4.GPIO_Mode=GPIO_MODE_AF_PP
PI4.GPIO_PuPd=GPIO_NOPULL
PI4.GPIO_Speed=GPIO_SPEED_FREQ_LOW
PI4.Mode=Slave_8_bits_External_Synchro
PI4.Signal=DCMI_D5
PI5.GPIO_Label=DCMI_VSYNC
PI5.GPIO_Mode=GPIO_MODE_AF_PP
PI5.GPIO_PuPd=GPIO_NOPULL
PI5.GPIO_Speed=GPIO_SPEED_FREQ_LOW
PI5.Mode=Slave_8_bits_External_Synchro
PI5.Signal=DCMI_VSYNC
PI6.GPIO_Label=DCMI_D6
PI6.GPIO_Mode=GPIO_MODE_AF_PP
PI6.GPIO_PuPd=GPIO_NOPULL
PI6.GPIO_Speed=GPIO_SPEED_FREQ_LOW
PI6.Mode=Slave_8_bits_External_Synchro
PI6.Signal=DCMI_D6
PI7.GPIO_Label=DCMI_D7
PI7.GPIO_Mode=GPIO_MODE_AF_PP
PI7.GPIO_PuPd=GPIO_NOPULL
PI7.GPIO_Speed=GPIO_SPEED_FREQ_LOW
PI7.Mode=Slave_8_bits_External_Synchro
PI7.Signal=DCMI_D7
PI9.GPIO_Label=LED3 [Red]
PI9.GPIO_Mode=GPIO_MODE_OUTPUT_PP
PI9.GPIO_ModeDefaultOutputPP=GPIO_MODE_OUTPUT_PP
PI9.GPIO_PuPd=GPIO_NOPULL
PI9.GPIO_Speed=GPIO_SPEED_FREQ_LOW
PI9.Signal=GPIO_Output
ProjectManager.HeapSize=0x200
ProjectManager.StackSize=0x400
ProjectManager.TargetToolchain=STM32CubeIDE
RCC.48MHZClocksFreq_Value=48000000
RCC.AHBFreq_Value=168000000
RCC.APB1CLKDivider=RCC_HCLK_DIV4
RCC.APB1Freq_Value=42000000
RCC.APB1TimFreq_Value=84000000
RCC.APB2CLKDivider=RCC_HCLK_DIV2
RCC.APB2Freq_Value=84000000
RCC.APB2TimFreq_Value=168000000
RCC.CortexFreq_Value=168000000
RCC.HCLKFreq_Value=168000000
RCC.HSE_VALUE=25000000
RCC.HSI_VALUE=16000000
RCC.PLLM=25
RCC.PLLN=336
RCC.PLLQ=7
RCC.RCC_MCO1Source=RCC_MCO1SOURCE_HSE
RCC.SYSCLKFreq_VALUE=168000000
RCC.SYSCLKSource=RCC_SYSCLKSOURCE_PLLCLK
RCC.VCOOutputFreq_Value=336000000
SH.COMP_DAC1_group.0=DAC_OUT1,DAC_OUT1
SH.FSMC_A0.0=FSMC_A0,21b-a1
SH.FSMC_A0.1=FSMC_A0,21b-a2
SH.FSMC_A0.2=FSMC_A0,21b-a3
SH.FSMC_A1.0=FSMC_A1,21b-a1
SH.FSMC_A1.1=FSMC_A1,21b-a2
SH.FSMC_A1.2=FSMC_A1,21b-a3
SH.FSMC_A10.0=FSMC_A10,21b-a1
SH.FSMC_A10.1=FSMC_A10,21b-a2
SH.FSMC_A10.2=FSMC_A10,21b-a3
SH.FSMC_A11.0=FSMC_A11,21b-a1
SH.FSMC_A11.1=FSMC_A11,21b-a2
SH.FSMC_A11.2=FSMC_A11,21b-a3
SH.FSMC_A12.0=FSMC_A12,21b-a1
SH.FSMC_A12.1=FSMC_A12,21b-a2
SH.FSMC_A12.2=FSMC_A12,21b-a3
SH.FSMC_A13.0=FSMC_A13,21b-a1
SH.FSMC_A13.1=FSMC_A13,21b-a2
SH.FSMC_A13.2=FSMC_A13,21b-a3
SH.FSMC_A14.0=FSMC_A14,21b-a1
SH.FSMC_A14.1=FSMC_A14,21b-a2
SH.FSMC_A14.2=FSMC_A14,21b-a3
SH.FSMC_A15.0=FSMC_A15,21b-a1
SH.FSMC_A15.1=FSMC_A15,21b-a2
SH.FSMC_A15.2=FSMC_A15,21b-a3
SH.FSMC_A16_CLE.0=FSMC_A16,21b-a1
SH.FSMC_A16_CLE.1=FSMC_A16,21b-a2
SH.FSMC_A16_CLE.2=FSMC_A16,21b-a3
SH.FSMC_A17_ALE.0=FSMC_A17,21b-a1
SH.FSMC_A17_ALE.1=FSMC_A17,21b-a2
SH.FSMC_A17_ALE.2=FSMC_A17,21b-a3
SH.FSMC_A18.0=FSMC_A18,21b-a1
SH.FSMC_A18.1=FSMC_A18,21b-a2
SH.FSMC_A18.2=FSMC_A18,21b-a3
SH.FSMC_A19.0=FSMC_A19,21b-a1
SH.FSMC_A19.1=FSMC_A19,21b-a2
SH.FSMC_A19.2=FSMC_A19,21b-a3
SH.FSMC_A2.0=FSMC_A2,21b-a1
SH.FSMC_A2.1=FSMC_A2,21b-a2
SH.FSMC_A2.2=FSMC_A2,21b-a3
SH.FSMC_A20.0=FSMC_A20,21b-a1
SH.FSMC_A20.1=FSMC_A20,21b-a2
SH.FSMC_A20.2=FSMC_A20,21b-a3
SH.FSMC_A3.0=FSMC_A3,21b-a1
SH.FSMC_A3.1=FSMC_A3,21b-a2
SH.FSMC_A3.2=FSMC_A3,21b-a3
SH.FSMC_A4.0=FSMC_A4,21b-a1
SH.FSMC_A4.1=FSMC_A4,21b-a2
SH.FSMC_A4.2=FSMC_A4,21b-a3
SH.FSMC_A5.0=FSMC_A5,21b-a1
SH.FSMC_A5.1=FSMC_A5,21b-a2
SH.FSMC_A5.2=FSMC_A5,21b-a3
SH.FSMC_A6.0=FSMC_A6,21b-a1
SH.FSMC_A6.1=FSMC_A6,21b-a2
SH.FSMC_A6.2=FSMC_A6,21b-a3
SH.FSMC_A7.0=FSMC_A7,21b-a1
SH.FSMC_A7.1=FSMC_A7,21b-a2
SH.FSMC_A7.2=FSMC_A7,21b-a3
SH.FSMC_A8.0=FSMC_A8,21b-a1
SH.FSMC_A8.1=FSMC_A8,21b-a2
SH.FSMC_A8.2=FSMC_A8,21b-a3
SH.FSMC_A9.0=FSMC_A9,21b-a1
SH.FSMC_A9.1=FSMC_A9,21b-a2
SH.FSMC_A9.2=FSMC_A9,21b-a3
SH.FSMC_CLK.0=FSMC_CLK
SH.FSMC_D0_DA0.0=FSMC_D0,16b-d1
SH.FSMC_D0_DA0.1=FSMC_D0,16b-d2
SH.FSMC_D0_DA0.2=FSMC_D0,16b-d3
SH.FSMC_D10_DA10.0=FSMC_D10,16b-d1
SH.FSMC_D10_DA10.1=FSMC_D10,16b-d2
SH.FSMC_D10_DA10.2=FSMC_D10,16b-d3
SH.FSMC_D11_DA11.0=FSMC_D11,16b-d1
SH.FSMC_D11_DA11.1=FSMC_D11,16b-d2
SH.FSMC_D11_DA11.2=FSMC_D11,16b-d3
SH.FSMC_D12_DA12.0=FSMC_D12,16b-d1
SH.FSMC_D12_DA12.1=FSMC_D12,16b-d2
SH.FSMC_D12_DA12.2=FSMC_D12,16b-d3
SH.FSMC_D13_DA13.0=FSMC_D13,16b-d1
SH.FSMC_D13_DA13.1=FSMC_D13,16b-d2
SH.FSMC_D13_DA13.2=FSMC_D13,16b-d3
SH.FSMC_D14_DA14.0=FSMC_D14,16b-d1
SH.FSMC_D14_DA14.1=FSMC_D14,16b-d2
SH.FSMC_D14_DA14.2=FSMC_D14,16b-d3
SH.FSMC_D15_DA15.0=FSMC_D15,16b-d1
SH.FSMC_D15_DA15.1=FSMC_D15,16b-d2
SH.FSMC_D15_DA15.2=FSMC_D15,16b-d3
SH.FSMC_D1_DA1.0=FSMC_D1,16b-d1
SH.FSMC_D1_DA1.1=FSMC_D1,16b-d2
SH.FSMC_D1_DA1.2=FSMC_D1,16b-d3
SH.FSMC_D2_DA2.0=FSMC_D2,16b-d1
SH.FSMC_D2_DA2.1=FSMC_D2,16b-d2
SH.FSMC_D2_DA2.2=FSMC_D2,16b-d3
SH.FSMC_D3_DA3.0=FSMC_D3,16b-d1
SH.FSMC_D3_DA3.1=FSMC_D3,16b-d2
SH.FSMC_D3_DA3.2=FSMC_D3,16b-d3
SH.FSMC_D4_DA4.0=FSMC_D4,16b-d1
SH.FSMC_D4_DA4.1=FSMC_D4,16b-d2
SH.FSMC_D4_DA4.2=FSMC_D4,16b-d3
SH.FSMC_D5_DA5.0=FSMC_D5,16b-d1
SH.FSMC_D5_DA5.1=FSMC_D5,16b-d2
SH.FSMC_D5_DA5.2=FSMC_D5,16b-d3
SH.FSMC_D6_DA6.0=FSMC_D6,16b-d1
SH.FSMC_D6_DA6.1=FSMC_D6,16b-d2
SH.FSMC_D6_DA6.2=FSMC_D6,16b-d3
SH.FSMC_D7_DA7.0=FSMC_D7,16b-d1
SH.FSMC_D7_DA7.1=FSMC_D7,16b-d2
SH.FSMC_D7_DA7.2=FSMC_D7,16b-d3
SH.FSMC_D8_DA8.0=FSMC_D8,16b-d1
SH.FSMC_D8_DA8.1=FSMC_D8,16b-d2
SH.FSMC_D8_DA8.2=FSMC_D8,16b-d3
SH.FSMC_D9_DA9.0=FSMC_D9,16b-d1
SH.FSMC_D9_DA9.1=FSMC_D9,16b-d2
SH.FSMC_D9_DA9.2=FSMC_D9,16b-d3
SH.FSMC_NBL0.0=FSMC_NBL0,2ByteEnable2
SH.FSMC_NBL1.0=FSMC_NBL1,2ByteEnable2
SH.FSMC_NL.0=FSMC_NL
SH.FSMC_NOE.0=FSMC_NOE,NorFlash1
SH.FSMC_NOE.1=FSMC_NOE,Sram2
SH.FSMC_NOE.2=FSMC_NOE,Sram3
SH.FSMC_NWAIT.0=FSMC_NWAIT
SH.FSMC_NWE.0=FSMC_NWE,NorFlash1
SH.FSMC_NWE.1=FSMC_NWE,Sram2
SH.FSMC_NWE.2=FSMC_NWE,Sram3
SH.S_TIM3_CH1.0=TIM3_CH1,Encoder_Interface
SH.S_TIM3_CH2.0=TIM3_CH2,Encoder_Interface
USART3.VirtualMode=VM_ASYNC
USB_DEVICE.CLASS_NAME_FS=CUSTOM_HID
USB_DEVICE.VirtualMode-CUSTOM_HID_FS=CustomHid
USB_DEVICE.VirtualModeFS=Custom_Hid_FS
USB_OTG_FS.VirtualMode=Device_Only
VP_USB_DEVICE_VS_USB_DEVICE_CUSTOM_HID_FS.Mode=CUSTOM_HID_FS
board=STM3240G-EVAL

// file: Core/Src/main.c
/* USER CODE BEGIN Header */
/**
 ******************************************************************************
 * @file           : main.c
 * @brief          : Main program body
 ******************************************************************************
 * @attention
 *
 * Copyright (c) 2023 STMicroelectronics.
 * All rights reserved.
 *
 * This software is licensed under terms that can be found in the LICENSE file
 * in the root directory of this software component.
 * If no LICENSE file comes with this software, it is provided AS-IS.
 *
 ******************************************************************************
 */
/* USER CODE END Header */
#include "main.h"
#include "usb_device.h"

/* USER CODE BEGIN Includes */
// #include "caps_lock.h"

//extern uint8_t caps_lock;
/* USER CODE END Includes */

ADC_HandleTypeDef hadc3;

DAC_HandleTypeDef hdac;

DCMI_HandleTypeDef hdcmi;

I2C_HandleTypeDef hi2c1;

TIM_HandleTypeDef htim3;

UART_HandleTypeDef huart3;

NOR_HandleTypeDef hnor1;
SRAM_HandleTypeDef hsram2;
SRAM_HandleTypeDef hsram3;

/* USER CODE BEGIN PV */
extern USBD_HandleTypeDef hUsbDeviceFS;

typedef struct
{
	uint8_t REPORT_ID;
	uint8_t MODIFIER;
	uint8_t RESERVED;
	uint8_t KEYCODE1;
	uint8_t KEYCODE2;
	uint8_t KEYCODE3;
	uint8_t KEYCODE4;
	uint8_t KEYCODE5;
	uint8_t KEYCODE6;
}subKeyBoard;

subKeyBoard keyBoardHIDsub = {1,0,0,0,0,0,0,0,0};

typedef struct
{
	uint8_t REPORT_ID;
	uint8_t buttons;
	uint8_t x;
	uint8_t y;
	uint8_t wheel;
}mouse_t;

mouse_t mouse_message = {2,0,0,0,0};

typedef struct
{
	uint8_t REPORT_ID;
	uint8_t volume;
} multimedia_t;

multimedia_t volume_message = {3,0};
/* USER CODE END PV */

void SystemClock_Config(void);
static void MX_GPIO_Init(void);
static void MX_ADC3_Init(void);
static void MX_DAC_Init(void);
static void MX_DCMI_Init(void);
static void MX_FSMC_Init(void);
static void MX_USART3_UART_Init(void);
static void MX_TIM3_Init(void);
static void MX_I2C1_Init(void);

int main(void)
{

  /* MCU Configuration--------------------------------------------------------*/

  /* Reset of all peripherals, Initializes the Flash interface and the Systick. */
  HAL_Init();

  /* Configure the system clock */
  SystemClock_Config();

  /* Initialize all configured peripherals */
  MX_GPIO_Init();
  MX_ADC3_Init();
  MX_DAC_Init();
  MX_DCMI_Init();
  MX_FSMC_Init();
  MX_USART3_UART_Init();
  MX_TIM3_Init();
  MX_USB_DEVICE_Init();
  MX_I2C1_Init();
  /* USER CODE BEGIN 2 */
	BSP_LCD_Init();
	BSP_LCD_SetBackColor(LCD_COLOR_WHITE);
	BSP_LCD_Clear(LCD_COLOR_WHITE);
	BSP_LCD_SetTextColor(LCD_COLOR_BLACK);
	BSP_LCD_SetFont(&Font24);
	BSP_LCD_DisplayStringAt(0, 0, (uint8_t *)"LCD", CENTER_MODE);
	BSP_LCD_DisplayStringAt(0, 30, (uint8_t *)"Volume control", CENTER_MODE);
	BSP_PB_Init(BUTTON_KEY, BUTTON_MODE_GPIO);
	BSP_LED_Init(LED1);

	HAL_TIM_Encoder_Start_IT(&htim3, TIM_CHANNEL_ALL);
	HAL_GetTick();
	TIM3->CNT = 30000;
	uint32_t rot_count = TIM3->CNT;

  /* USER CODE END 2 */

  /* Infinite loop */
  /* USER CODE BEGIN WHILE */
	uint8_t usage_switch = 0;
	while (1)
	{
		if(BSP_PB_GetState(BUTTON_KEY) == RESET){
			BSP_LED_On(LED1);
			while(BSP_PB_GetState(BUTTON_KEY) == RESET) continue;
			usage_switch = !usage_switch;
			if(usage_switch == 0) {
				BSP_LCD_DisplayStringAt(0, 30, (uint8_t *)"Volume control", CENTER_MODE);
			} else {
				BSP_LCD_DisplayStringAt(0, 30, (uint8_t *)"Scroll control", CENTER_MODE);
			}
		} else {
			BSP_LED_Off(LED1);
		}
		/// VOLUME control
		if(usage_switch == 0) {
			if (rot_count != TIM3->CNT) {
				if (rot_count > TIM3->CNT) {
					volume_message.volume = 0b0010000;		// increment volume
				} else {
					volume_message.volume = 0b0100000;		// decrement volume
				}
				USBD_CUSTOM_HID_SendReport(&hUsbDeviceFS,&volume_message,sizeof(volume_message));
				HAL_Delay(30);
				volume_message.volume = 0b00000000;
				USBD_CUSTOM_HID_SendReport(&hUsbDeviceFS,&volume_message,sizeof(volume_message));
				rot_count = TIM3->CNT;
			}
			if (HAL_GPIO_ReadPin(GPIOB, GPIO_PIN_6) == 0){
				while(HAL_GPIO_ReadPin(GPIOB, GPIO_PIN_6) == 0) continue;
				volume_message.volume = 0b1000000;			// mute
				USBD_CUSTOM_HID_SendReport(&hUsbDeviceFS,&volume_message,sizeof(volume_message));
			} else {
				volume_message.volume = 0b00000000;
				USBD_CUSTOM_HID_SendReport(&hUsbDeviceFS,&volume_message,sizeof(volume_message));
			}
		}
		// SCROLL control
		if(usage_switch == 1){
			if (rot_count != TIM3->CNT) {
				mouse_message.wheel = TIM3->CNT-rot_count;
				USBD_CUSTOM_HID_SendReport(&hUsbDeviceFS,&mouse_message,sizeof(mouse_message));
				rot_count = TIM3->CNT;
			}
			if (HAL_GPIO_ReadPin(GPIOB, GPIO_PIN_6) == 0){
				while(HAL_GPIO_ReadPin(GPIOB, GPIO_PIN_6) == 0) continue;
				keyBoardHIDsub.KEYCODE1 = 0x39;			// CAPS LOCK
				USBD_CUSTOM_HID_SendReport(&hUsbDeviceFS,&keyBoardHIDsub,sizeof(keyBoardHIDsub));
			} else {
				keyBoardHIDsub.KEYCODE1 = 0;
				USBD_CUSTOM_HID_SendReport(&hUsbDeviceFS,&keyBoardHIDsub,sizeof(keyBoardHIDsub));
			}

		}
		if (get_caps() == 0) {
			BSP_LCD_DisplayStringAt(0, 60, (uint8_t *)"caps lock off", CENTER_MODE);
		}
		if (get_caps() == 1) {
			BSP_LCD_DisplayStringAt(0, 60, (uint8_t *)"CAPS LOCK ON!", CENTER_MODE);
		}
    /* USER CODE END WHILE */

	}
}

void SystemClock_Config(void)
{
  RCC_OscInitTypeDef RCC_OscInitStruct = {0};
  RCC_ClkInitTypeDef RCC_ClkInitStruct = {0};

  /** Configure the main internal regulator output voltage
  */
  __HAL_RCC_PWR_CLK_ENABLE();
  __HAL_PWR_VOLTAGESCALING_CONFIG(PWR_REGULATOR_VOLTAGE_SCALE1);

  /** Initializes the RCC Oscillators according to the specified parameters
  * in the RCC_OscInitTypeDef structure.
  */
  RCC_OscInitStruct.OscillatorType = RCC_OSCILLATORTYPE_HSE;
  RCC_OscInitStruct.HSEState = RCC_HSE_ON;
  RCC_OscInitStruct.PLL.PLLState = RCC_PLL_ON;
  RCC_OscInitStruct.PLL.PLLSource = RCC_PLLSOURCE_HSE;
  RCC_OscInitStruct.PLL.PLLM = 25;
  RCC_OscInitStruct.PLL.PLLN = 336;
  RCC_OscInitStruct.PLL.PLLP = RCC_PLLP_DIV2;
  RCC_OscInitStruct.PLL.PLLQ = 7;
  if (HAL_RCC_OscConfig(&RCC_OscInitStruct) != HAL_OK)
  {
    Error_Handler();
  }

  /** Initializes the CPU, AHB and APB buses clocks
  */
  RCC_ClkInitStruct.ClockType = RCC_CLOCKTYPE_HCLK|RCC_CLOCKTYPE_SYSCLK
                              |RCC_CLOCKTYPE_PCLK1|RCC_CLOCKTYPE_PCLK2;
  RCC_ClkInitStruct.SYSCLKSource = RCC_SYSCLKSOURCE_PLLCLK;
  RCC_ClkInitStruct.AHBCLKDivider = RCC_SYSCLK_DIV1;
  RCC_ClkInitStruct.APB1CLKDivider = RCC_HCLK_DIV4;
  RCC_ClkInitStruct.APB2CLKDivider = RCC_HCLK_DIV2;

  if (HAL_RCC_ClockConfig(&RCC_ClkInitStruct, FLASH_LATENCY_5) != HAL_OK)
  {
    Error_Handler();
  }
  HAL_RCC_MCOConfig(RCC_MCO1, RCC_MCO1SOURCE_HSE, RCC_MCODIV_1);
}

static void MX_ADC3_Init(void)
{

  ADC_ChannelConfTypeDef sConfig = {0};

  /** Configure the global features of the ADC (Clock, Resolution, Data Alignment and number of conversion)
  */
  hadc3.Instance = ADC3;
  hadc3.Init.ClockPrescaler = ADC_CLOCK_SYNC_PCLK_DIV4;
  hadc3.Init.Resolution = ADC_RESOLUTION_12B;
  hadc3.Init.ScanConvMode = DISABLE;
  hadc3.Init.ContinuousConvMode = DISABLE;
  hadc3.Init.DiscontinuousConvMode = DISABLE;
  hadc3.Init.ExternalTrigConvEdge = ADC_EXTERNALTRIGCONVEDGE_NONE;
  hadc3.Init.ExternalTrigConv = ADC_SOFTWARE_START;
  hadc3.Init.DataAlign = ADC_DATAALIGN_RIGHT;
  hadc3.Init.NbrOfConversion = 1;
  hadc3.Init.DMAContinuousRequests = DISABLE;
  hadc3.Init.EOCSelection = ADC_EOC_SINGLE_CONV;
  if (HAL_ADC_Init(&hadc3) != HAL_OK)
  {
    Error_Handler();
  }

  /** Configure for the selected ADC regular channel its corresponding rank in the sequencer and its sample time.
  */
  sConfig.Channel = ADC_CHANNEL_7;
  sConfig.Rank = 1;
  sConfig.SamplingTime = ADC_SAMPLETIME_3CYCLES;
  if (HAL_ADC_ConfigChannel(&hadc3, &sConfig) != HAL_OK)
  {
    Error_Handler();
  }

}

static void MX_DAC_Init(void)
{

  DAC_ChannelConfTypeDef sConfig = {0};

  /** DAC Initialization
  */
  hdac.Instance = DAC;
  if (HAL_DAC_Init(&hdac) != HAL_OK)
  {
    Error_Handler();
  }

  /** DAC channel OUT1 config
  */
  sConfig.DAC_Trigger = DAC_TRIGGER_NONE;
  sConfig.DAC_OutputBuffer = DAC_OUTPUTBUFFER_ENABLE;
  if (HAL_DAC_ConfigChannel(&hdac, &sConfig, DAC_CHANNEL_1) != HAL_OK)
  {
    Error_Handler();
  }

}

static void MX_DCMI_Init(void)
{

  hdcmi.Instance = DCMI;
  hdcmi.Init.SynchroMode = DCMI_SYNCHRO_HARDWARE;
  hdcmi.Init.PCKPolarity = DCMI_PCKPOLARITY_FALLING;
  hdcmi.Init.VSPolarity = DCMI_VSPOLARITY_LOW;
  hdcmi.Init.HSPolarity = DCMI_HSPOLARITY_LOW;
  hdcmi.Init.CaptureRate = DCMI_CR_ALL_FRAME;
  hdcmi.Init.ExtendedDataMode = DCMI_EXTEND_DATA_8B;
  hdcmi.Init.JPEGMode = DCMI_JPEG_DISABLE;
  if (HAL_DCMI_Init(&hdcmi) != HAL_OK)
  {
    Error_Handler();
  }

}

static void MX_I2C1_Init(void)
{

  hi2c1.Instance = I2C1;
  hi2c1.Init.ClockSpeed = 100000;
  hi2c1.Init.DutyCycle = I2C_DUTYCYCLE_2;
  hi2c1.Init.OwnAddress1 = 0;
  hi2c1.Init.AddressingMode = I2C_ADDRESSINGMODE_7BIT;
  hi2c1.Init.DualAddressMode = I2C_DUALADDRESS_DISABLE;
  hi2c1.Init.OwnAddress2 = 0;
  hi2c1.Init.GeneralCallMode = I2C_GENERALCALL_DISABLE;
  hi2c1.Init.NoStretchMode = I2C_NOSTRETCH_DISABLE;
  if (HAL_I2C_Init(&hi2c1) != HAL_OK)
  {
    Error_Handler();
  }

}

static void MX_TIM3_Init(void)
{

  TIM_Encoder_InitTypeDef sConfig = {0};
  TIM_MasterConfigTypeDef sMasterConfig = {0};

  htim3.Instance = TIM3;
  htim3.Init.Prescaler = 0;
  htim3.Init.CounterMode = TIM_COUNTERMODE_UP;
  htim3.Init.Period = 65535;
  htim3.Init.ClockDivision = TIM_CLOCKDIVISION_DIV1;
  htim3.Init.AutoReloadPreload = TIM_AUTORELOAD_PRELOAD_DISABLE;
  sConfig.EncoderMode = TIM_ENCODERMODE_TI1;
  sConfig.IC1Polarity = TIM_ICPOLARITY_RISING;
  sConfig.IC1Selection = TIM_ICSELECTION_DIRECTTI;
  sConfig.IC1Prescaler = TIM_ICPSC_DIV1;
  sConfig.IC1Filter = 0;
  sConfig.IC2Polarity = TIM_ICPOLARITY_RISING;
  sConfig.IC2Selection = TIM_ICSELECTION_DIRECTTI;
  sConfig.IC2Prescaler = TIM_ICPSC_DIV1;
  sConfig.IC2Filter = 0;
  if (HAL_TIM_Encoder_Init(&htim3, &sConfig) != HAL_OK)
  {
    Error_Handler();
  }
  sMasterConfig.MasterOutputTrigger = TIM_TRGO_RESET;
  sMasterConfig.MasterSlaveMode = TIM_MASTERSLAVEMODE_DISABLE;
  if (HAL_TIMEx_MasterConfigSynchronization(&htim3, &sMasterConfig) != HAL_OK)
  {
    Error_Handler();
  }

}

static void MX_USART3_UART_Init(void)
{

  huart3.Instance = USART3;
  huart3.Init.BaudRate = 115200;
  huart3.Init.WordLength = UART_WORDLENGTH_8B;
  huart3.Init.StopBits = UART_STOPBITS_1;
  huart3.Init.Parity = UART_PARITY_NONE;
  huart3.Init.Mode = UART_MODE_TX_RX;
  huart3.Init.HwFlowCtl = UART_HWCONTROL_NONE;
  huart3.Init.OverSampling = UART_OVERSAMPLING_16;
  if (HAL_UART_Init(&huart3) != HAL_OK)
  {
    Error_Handler();
  }

}

static void MX_GPIO_Init(void)
{
  GPIO_InitTypeDef GPIO_InitStruct = {0};

  /* GPIO Ports Clock Enable */
  __HAL_RCC_GPIOE_CLK_ENABLE();
  __HAL_RCC_GPIOB_CLK_ENABLE();
  __HAL_RCC_GPIOG_CLK_ENABLE();
  __HAL_RCC_GPIOD_CLK_ENABLE();
  __HAL_RCC_GPIOC_CLK_ENABLE();
  __HAL_RCC_GPIOA_CLK_ENABLE();
  __HAL_RCC_GPIOI_CLK_ENABLE();
  __HAL_RCC_GPIOH_CLK_ENABLE();
  __HAL_RCC_GPIOF_CLK_ENABLE();

  /*Configure GPIO pin Output Level */
  HAL_GPIO_WritePin(GPIOG, SmartCard_CMDVCC_Pin|LED2_Pin|LED1_Pin, GPIO_PIN_RESET);

  /*Configure GPIO pin Output Level */
  HAL_GPIO_WritePin(LED3_GPIO_Port, LED3_Pin, GPIO_PIN_RESET);

  /*Configure GPIO pin Output Level */
  HAL_GPIO_WritePin(GPIOH, SmartCard_3_5V_Pin|OTG_FS_PowerSwitchOn_Pin, GPIO_PIN_RESET);

  /*Configure GPIO pin Output Level */
  HAL_GPIO_WritePin(LED4_GPIO_Port, LED4_Pin, GPIO_PIN_RESET);

  /*Configure GPIO pin Output Level */
  HAL_GPIO_WritePin(SmartCard_RST_GPIO_Port, SmartCard_RST_Pin, GPIO_PIN_RESET);

  /*Configure GPIO pins : MII_TXD1_Pin MII_TXD0_Pin MII_TX_EN_Pin */
  GPIO_InitStruct.Pin = MII_TXD1_Pin|MII_TXD0_Pin|MII_TX_EN_Pin;
  GPIO_InitStruct.Mode = GPIO_MODE_AF_PP;
  GPIO_InitStruct.Pull = GPIO_NOPULL;
  GPIO_InitStruct.Speed = GPIO_SPEED_FREQ_LOW;
  GPIO_InitStruct.Alternate = GPIO_AF11_ETH;
  HAL_GPIO_Init(GPIOG, &GPIO_InitStruct);

  /*Configure GPIO pins : MicroSDCard_CLK_Pin MicroSDCard_D1_Pin MicroSDCard_D0_Pin */
  GPIO_InitStruct.Pin = MicroSDCard_CLK_Pin|MicroSDCard_D1_Pin|MicroSDCard_D0_Pin;
  GPIO_InitStruct.Mode = GPIO_MODE_AF_PP;
  GPIO_InitStruct.Pull = GPIO_NOPULL;
  GPIO_InitStruct.Speed = GPIO_SPEED_FREQ_VERY_HIGH;
  GPIO_InitStruct.Alternate = GPIO_AF12_SDIO;
  HAL_GPIO_Init(GPIOC, &GPIO_InitStruct);

  /*Configure GPIO pin : PB6 */
  GPIO_InitStruct.Pin = GPIO_PIN_6;
  GPIO_InitStruct.Mode = GPIO_MODE_INPUT;
  GPIO_InitStruct.Pull = GPIO_PULLDOWN;
  HAL_GPIO_Init(GPIOB, &GPIO_InitStruct);

  /*Configure GPIO pin : User_Button_Pin */
  GPIO_InitStruct.Pin = User_Button_Pin;
  GPIO_InitStruct.Mode = GPIO_MODE_EVT_RISING;
  GPIO_InitStruct.Pull = GPIO_NOPULL;
  HAL_GPIO_Init(User_Button_GPIO_Port, &GPIO_InitStruct);

  /*Configure GPIO pins : SmartCard_CMDVCC_Pin LED2_Pin LED1_Pin */
  GPIO_InitStruct.Pin = SmartCard_CMDVCC_Pin|LED2_Pin|LED1_Pin;
  GPIO_InitStruct.Mode = GPIO_MODE_OUTPUT_PP;
  GPIO_InitStruct.Pull = GPIO_NOPULL;
  GPIO_InitStruct.Speed = GPIO_SPEED_FREQ_LOW;
  HAL_GPIO_Init(GPIOG, &GPIO_InitStruct);

  /*Configure GPIO pins : I2S_SD_Pin I2S_WS_Pin */
  GPIO_InitStruct.Pin = I2S_SD_Pin|I2S_WS_Pin;
  GPIO_InitStruct.Mode = GPIO_MODE_AF_PP;
  GPIO_InitStruct.Pull = GPIO_NOPULL;
  GPIO_InitStruct.Speed = GPIO_SPEED_FREQ_LOW;
  GPIO_InitStruct.Alternate = GPIO_AF5_SPI2;
  HAL_GPIO_Init(GPIOI, &GPIO_InitStruct);

  /*Configure GPIO pin : IO_Expander_INT_Pin */
  GPIO_InitStruct.Pin = IO_Expander_INT_Pin;
  GPIO_InitStruct.Mode = GPIO_MODE_EVT_RISING;
  GPIO_InitStruct.Pull = GPIO_NOPULL;
  HAL_GPIO_Init(IO_Expander_INT_GPIO_Port, &GPIO_InitStruct);

  /*Configure GPIO pin : LED3_Pin */
  GPIO_InitStruct.Pin = LED3_Pin;
  GPIO_InitStruct.Mode = GPIO_MODE_OUTPUT_PP;
  GPIO_InitStruct.Pull = GPIO_NOPULL;
  GPIO_InitStruct.Speed = GPIO_SPEED_FREQ_LOW;
  HAL_GPIO_Init(LED3_GPIO_Port, &GPIO_InitStruct);

  /*Configure GPIO pin : MicroSDCard_CMD_Pin */
  GPIO_InitStruct.Pin = MicroSDCard_CMD_Pin;
  GPIO_InitStruct.Mode = GPIO_MODE_AF_PP;
  GPIO_InitStruct.Pull = GPIO_NOPULL;
  GPIO_InitStruct.Speed = GPIO_SPEED_FREQ_VERY_HIGH;
  GPIO_InitStruct.Alternate = GPIO_AF12_SDIO;
  HAL_GPIO_Init(MicroSDCard_CMD_GPIO_Port, &GPIO_InitStruct);

  /*Configure GPIO pins : SmartCard_3_5V_Pin OTG_FS_PowerSwitchOn_Pin */
  GPIO_InitStruct.Pin = SmartCard_3_5V_Pin|OTG_FS_PowerSwitchOn_Pin;
  GPIO_InitStruct.Mode = GPIO_MODE_OUTPUT_PP;
  GPIO_InitStruct.Pull = GPIO_NOPULL;
  GPIO_InitStruct.Speed = GPIO_SPEED_FREQ_LOW;
  HAL_GPIO_Init(GPIOH, &GPIO_InitStruct);

  /*Configure GPIO pin : MII_RX_ER_Pin */
  GPIO_InitStruct.Pin = MII_RX_ER_Pin;
  GPIO_InitStruct.Mode = GPIO_MODE_AF_PP;
  GPIO_InitStruct.Pull = GPIO_NOPULL;
  GPIO_InitStruct.Speed = GPIO_SPEED_FREQ_LOW;
  GPIO_InitStruct.Alternate = GPIO_AF11_ETH;
  HAL_GPIO_Init(MII_RX_ER_GPIO_Port, &GPIO_InitStruct);

  /*Configure GPIO pin : ULPI_DIR_Pin */
  GPIO_InitStruct.Pin = ULPI_DIR_Pin;
  GPIO_InitStruct.Mode = GPIO_MODE_AF_PP;
  GPIO_InitStruct.Pull = GPIO_NOPULL;
  GPIO_InitStruct.Speed = GPIO_SPEED_FREQ_VERY_HIGH;
  GPIO_InitStruct.Alternate = GPIO_AF10_OTG_HS;
  HAL_GPIO_Init(ULPI_DIR_GPIO_Port, &GPIO_InitStruct);

  /*Configure GPIO pin : MicroSDCard_Detect_Pin */
  GPIO_InitStruct.Pin = MicroSDCard_Detect_Pin;
  GPIO_InitStruct.Mode = GPIO_MODE_INPUT;
  GPIO_InitStruct.Pull = GPIO_PULLUP;
  HAL_GPIO_Init(MicroSDCard_Detect_GPIO_Port, &GPIO_InitStruct);

  /*Configure GPIO pins : MII_CRS_Pin MII_COL_Pin MII_RXD2_Pin MII_RXD3_Pin */
  GPIO_InitStruct.Pin = MII_CRS_Pin|MII_COL_Pin|MII_RXD2_Pin|MII_RXD3_Pin;
  GPIO_InitStruct.Mode = GPIO_MODE_AF_PP;
  GPIO_InitStruct.Pull = GPIO_NOPULL;
  GPIO_InitStruct.Speed = GPIO_SPEED_FREQ_LOW;
  GPIO_InitStruct.Alternate = GPIO_AF11_ETH;
  HAL_GPIO_Init(GPIOH, &GPIO_InitStruct);

  /*Configure GPIO pin : MCO_Pin */
  GPIO_InitStruct.Pin = MCO_Pin;
  GPIO_InitStruct.Mode = GPIO_MODE_AF_PP;
  GPIO_InitStruct.Pull = GPIO_NOPULL;
  GPIO_InitStruct.Speed = GPIO_SPEED_FREQ_LOW;
  GPIO_InitStruct.Alternate = GPIO_AF0_MCO;
  HAL_GPIO_Init(MCO_GPIO_Port, &GPIO_InitStruct);

  /*Configure GPIO pin : LED4_Pin */
  GPIO_InitStruct.Pin = LED4_Pin;
  GPIO_InitStruct.Mode = GPIO_MODE_OUTPUT_PP;
  GPIO_InitStruct.Pull = GPIO_NOPULL;
  GPIO_InitStruct.Speed = GPIO_SPEED_FREQ_LOW;
  HAL_GPIO_Init(LED4_GPIO_Port, &GPIO_InitStruct);

  /*Configure GPIO pin : ULPI_NXT_Pin */
  GPIO_InitStruct.Pin = ULPI_NXT_Pin;
  GPIO_InitStruct.Mode = GPIO_MODE_AF_PP;
  GPIO_InitStruct.Pull = GPIO_NOPULL;
  GPIO_InitStruct.Speed = GPIO_SPEED_FREQ_VERY_HIGH;
  GPIO_InitStruct.Alternate = GPIO_AF10_OTG_HS;
  HAL_GPIO_Init(ULPI_NXT_GPIO_Port, &GPIO_InitStruct);

  /*Configure GPIO pin : SmartCard_CLK_Pin */
  GPIO_InitStruct.Pin = SmartCard_CLK_Pin;
  GPIO_InitStruct.Mode = GPIO_MODE_AF_PP;
  GPIO_InitStruct.Pull = GPIO_NOPULL;
  GPIO_InitStruct.Speed = GPIO_SPEED_FREQ_LOW;
  GPIO_InitStruct.Alternate = GPIO_AF8_USART6;
  HAL_GPIO_Init(SmartCard_CLK_GPIO_Port, &GPIO_InitStruct);

  /*Configure GPIO pin : SmartCard_RST_Pin */
  GPIO_InitStruct.Pin = SmartCard_RST_Pin;
  GPIO_InitStruct.Mode = GPIO_MODE_OUTPUT_PP;
  GPIO_InitStruct.Pull = GPIO_NOPULL;
  GPIO_InitStruct.Speed = GPIO_SPEED_FREQ_LOW;
  HAL_GPIO_Init(SmartCard_RST_GPIO_Port, &GPIO_InitStruct);

  /*Configure GPIO pin : SmartCard_OFF_Pin */
  GPIO_InitStruct.Pin = SmartCard_OFF_Pin;
  GPIO_InitStruct.Mode = GPIO_MODE_INPUT;
  GPIO_InitStruct.Pull = GPIO_NOPULL;
  HAL_GPIO_Init(SmartCard_OFF_GPIO_Port, &GPIO_InitStruct);

  /*Configure GPIO pin : ULPI_STP_Pin */
  GPIO_InitStruct.Pin = ULPI_STP_Pin;
  GPIO_InitStruct.Mode = GPIO_MODE_AF_PP;
  GPIO_InitStruct.Pull = GPIO_NOPULL;
  GPIO_InitStruct.Speed = GPIO_SPEED_FREQ_VERY_HIGH;
  GPIO_InitStruct.Alternate = GPIO_AF10_OTG_HS;
  HAL_GPIO_Init(ULPI_STP_GPIO_Port, &GPIO_InitStruct);

  /*Configure GPIO pins : MII_MDC_Pin MII_TXD2_Pin MII_TX_CLK_Pin MII_RXD0_Pin
                           MII_RXD1_Pin */
  GPIO_InitStruct.Pin = MII_MDC_Pin|MII_TXD2_Pin|MII_TX_CLK_Pin|MII_RXD0_Pin
                          |MII_RXD1_Pin;
  GPIO_InitStruct.Mode = GPIO_MODE_AF_PP;
  GPIO_InitStruct.Pull = GPIO_NOPULL;
  GPIO_InitStruct.Speed = GPIO_SPEED_FREQ_LOW;
  GPIO_InitStruct.Alternate = GPIO_AF11_ETH;
  HAL_GPIO_Init(GPIOC, &GPIO_InitStruct);

  /*Configure GPIO pin : SW1_Pin */
  GPIO_InitStruct.Pin = SW1_Pin;
  GPIO_InitStruct.Mode = GPIO_MODE_INPUT;
  GPIO_InitStruct.Pull = GPIO_NOPULL;
  HAL_GPIO_Init(SW1_GPIO_Port, &GPIO_InitStruct);

  /*Configure GPIO pins : MII_RX_CLK_RMII_REF_CLK_Pin MII_MDIO_Pin MII_RX_DV_RMII_CRSDV_Pin */
  GPIO_InitStruct.Pin = MII_RX_CLK_RMII_REF_CLK_Pin|MII_MDIO_Pin|MII_RX_DV_RMII_CRSDV_Pin;
  GPIO_InitStruct.Mode = GPIO_MODE_AF_PP;
  GPIO_InitStruct.Pull = GPIO_NOPULL;
  GPIO_InitStruct.Speed = GPIO_SPEED_FREQ_LOW;
  GPIO_InitStruct.Alternate = GPIO_AF11_ETH;
  HAL_GPIO_Init(GPIOA, &GPIO_InitStruct);

  /*Configure GPIO pins : ULPI_CLK_Pin ULPI_D0_Pin */
  GPIO_InitStruct.Pin = ULPI_CLK_Pin|ULPI_D0_Pin;
  GPIO_InitStruct.Mode = GPIO_MODE_AF_PP;
  GPIO_InitStruct.Pull = GPIO_NOPULL;
  GPIO_InitStruct.Speed = GPIO_SPEED_FREQ_VERY_HIGH;
  GPIO_InitStruct.Alternate = GPIO_AF10_OTG_HS;
  HAL_GPIO_Init(GPIOA, &GPIO_InitStruct);

  /*Configure GPIO pins : ULPI_D5_Pin ULPI_D6_Pin ULPI_D2_Pin ULPI_D1_Pin
                           ULPI_D3_Pin ULPI_D4_Pin */
  GPIO_InitStruct.Pin = ULPI_D5_Pin|ULPI_D6_Pin|ULPI_D2_Pin|ULPI_D1_Pin
                          |ULPI_D3_Pin|ULPI_D4_Pin;
  GPIO_InitStruct.Mode = GPIO_MODE_AF_PP;
  GPIO_InitStruct.Pull = GPIO_NOPULL;
  GPIO_InitStruct.Speed = GPIO_SPEED_FREQ_VERY_HIGH;
  GPIO_InitStruct.Alternate = GPIO_AF10_OTG_HS;
  HAL_GPIO_Init(GPIOB, &GPIO_InitStruct);

  /*Configure GPIO pin : OTG_FS_OverCurrent_Pin */
  GPIO_InitStruct.Pin = OTG_FS_OverCurrent_Pin;
  GPIO_InitStruct.Mode = GPIO_MODE_EVT_RISING;
  GPIO_InitStruct.Pull = GPIO_NOPULL;
  HAL_GPIO_Init(OTG_FS_OverCurrent_GPIO_Port, &GPIO_InitStruct);

  /*Configure GPIO pin : MII_INT_Pin */
  GPIO_InitStruct.Pin = MII_INT_Pin;
  GPIO_InitStruct.Mode = GPIO_MODE_EVT_RISING;
  GPIO_InitStruct.Pull = GPIO_NOPULL;
  HAL_GPIO_Init(MII_INT_GPIO_Port, &GPIO_InitStruct);

}

/* FSMC initialization function */
static void MX_FSMC_Init(void)
{

  FSMC_NORSRAM_TimingTypeDef Timing = {0};

  /** Perform the NOR1 memory initialization sequence
  */
  hnor1.Instance = FSMC_NORSRAM_DEVICE;
  hnor1.Extended = FSMC_NORSRAM_EXTENDED_DEVICE;
  /* hnor1.Init */
  hnor1.Init.NSBank = FSMC_NORSRAM_BANK1;
  hnor1.Init.DataAddressMux = FSMC_DATA_ADDRESS_MUX_DISABLE;
  hnor1.Init.MemoryType = FSMC_MEMORY_TYPE_NOR;
  hnor1.Init.MemoryDataWidth = FSMC_NORSRAM_MEM_BUS_WIDTH_16;
  hnor1.Init.BurstAccessMode = FSMC_BURST_ACCESS_MODE_DISABLE;
  hnor1.Init.WaitSignalPolarity = FSMC_WAIT_SIGNAL_POLARITY_LOW;
  hnor1.Init.WrapMode = FSMC_WRAP_MODE_DISABLE;
  hnor1.Init.WaitSignalActive = FSMC_WAIT_TIMING_BEFORE_WS;
  hnor1.Init.WriteOperation = FSMC_WRITE_OPERATION_DISABLE;
  hnor1.Init.WaitSignal = FSMC_WAIT_SIGNAL_DISABLE;
  hnor1.Init.ExtendedMode = FSMC_EXTENDED_MODE_DISABLE;
  hnor1.Init.AsynchronousWait = FSMC_ASYNCHRONOUS_WAIT_DISABLE;
  hnor1.Init.WriteBurst = FSMC_WRITE_BURST_DISABLE;
  hnor1.Init.PageSize = FSMC_PAGE_SIZE_NONE;
  /* Timing */
  Timing.AddressSetupTime = 15;
  Timing.AddressHoldTime = 15;
  Timing.DataSetupTime = 255;
  Timing.BusTurnAroundDuration = 15;
  Timing.CLKDivision = 16;
  Timing.DataLatency = 17;
  Timing.AccessMode = FSMC_ACCESS_MODE_A;
  /* ExtTiming */

  if (HAL_NOR_Init(&hnor1, &Timing, NULL) != HAL_OK)
  {
    Error_Handler( );
  }

  /** Perform the SRAM2 memory initialization sequence
  */
  hsram2.Instance = FSMC_NORSRAM_DEVICE;
  hsram2.Extended = FSMC_NORSRAM_EXTENDED_DEVICE;
  /* hsram2.Init */
  hsram2.Init.NSBank = FSMC_NORSRAM_BANK2;
  hsram2.Init.DataAddressMux = FSMC_DATA_ADDRESS_MUX_DISABLE;
  hsram2.Init.MemoryType = FSMC_MEMORY_TYPE_SRAM;
  hsram2.Init.MemoryDataWidth = FSMC_NORSRAM_MEM_BUS_WIDTH_16;
  hsram2.Init.BurstAccessMode = FSMC_BURST_ACCESS_MODE_DISABLE;
  hsram2.Init.WaitSignalPolarity = FSMC_WAIT_SIGNAL_POLARITY_LOW;
  hsram2.Init.WrapMode = FSMC_WRAP_MODE_DISABLE;
  hsram2.Init.WaitSignalActive = FSMC_WAIT_TIMING_BEFORE_WS;
  hsram2.Init.WriteOperation = FSMC_WRITE_OPERATION_DISABLE;
  hsram2.Init.WaitSignal = FSMC_WAIT_SIGNAL_DISABLE;
  hsram2.Init.ExtendedMode = FSMC_EXTENDED_MODE_DISABLE;
  hsram2.Init.AsynchronousWait = FSMC_ASYNCHRONOUS_WAIT_DISABLE;
  hsram2.Init.WriteBurst = FSMC_WRITE_BURST_DISABLE;
  hsram2.Init.PageSize = FSMC_PAGE_SIZE_NONE;
  /* Timing */
  Timing.AddressSetupTime = 15;
  Timing.AddressHoldTime = 15;
  Timing.DataSetupTime = 255;
  Timing.BusTurnAroundDuration = 15;
  Timing.CLKDivision = 16;
  Timing.DataLatency = 17;
  Timing.AccessMode = FSMC_ACCESS_MODE_A;
  /* ExtTiming */

  if (HAL_SRAM_Init(&hsram2, &Timing, NULL) != HAL_OK)
  {
    Error_Handler( );
  }

  /** Perform the SRAM3 memory initialization sequence
  */
  hsram3.Instance = FSMC_NORSRAM_DEVICE;
  hsram3.Extended = FSMC_NORSRAM_EXTENDED_DEVICE;
  /* hsram3.Init */
  hsram3.Init.NSBank = FSMC_NORSRAM_BANK3;
  hsram3.Init.DataAddressMux = FSMC_DATA_ADDRESS_MUX_DISABLE;
  hsram3.Init.MemoryType = FSMC_MEMORY_TYPE_SRAM;
  hsram3.Init.MemoryDataWidth = FSMC_NORSRAM_MEM_BUS_WIDTH_16;
  hsram3.Init.BurstAccessMode = FSMC_BURST_ACCESS_MODE_DISABLE;
  hsram3.Init.WaitSignalPolarity = FSMC_WAIT_SIGNAL_POLARITY_LOW;
  hsram3.Init.WrapMode = FSMC_WRAP_MODE_DISABLE;
  hsram3.Init.WaitSignalActive = FSMC_WAIT_TIMING_BEFORE_WS;
  hsram3.Init.WriteOperation = FSMC_WRITE_OPERATION_DISABLE;
  hsram3.Init.WaitSignal = FSMC_WAIT_SIGNAL_DISABLE;
  hsram3.Init.ExtendedMode = FSMC_EXTENDED_MODE_DISABLE;
  hsram3.Init.AsynchronousWait = FSMC_ASYNCHRONOUS_WAIT_DISABLE;
  hsram3.Init.WriteBurst = FSMC_WRITE_BURST_DISABLE;
  hsram3.Init.PageSize = FSMC_PAGE_SIZE_NONE;
  /* Timing */
  Timing.AddressSetupTime = 15;
  Timing.AddressHoldTime = 15;
  Timing.DataSetupTime = 255;
  Timing.BusTurnAroundDuration = 15;
  Timing.CLKDivision = 16;
  Timing.DataLatency = 17;
  Timing.AccessMode = FSMC_ACCESS_MODE_A;
  /* ExtTiming */

  if (HAL_SRAM_Init(&hsram3, &Timing, NULL) != HAL_OK)
  {
    Error_Handler( );
  }

}

void Error_Handler(void)
{
	__disable_irq();
	while (1)
	{
	}
}
